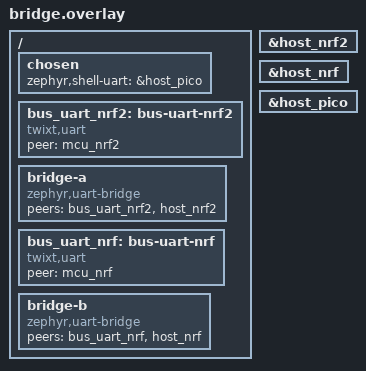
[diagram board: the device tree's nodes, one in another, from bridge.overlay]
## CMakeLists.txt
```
# Copyright (c) 2026 Christoph Jans <jans.christoph@gmail.com>
# SPDX-License-Identifier: Apache-2.0

cmake_minimum_required(VERSION 3.20.0)

# One image per MCU: nrf2 and nrf are boards with a shell, the bridge passes their shells on
# to the host. MCU picks which MCU of twixt_mcus.dtsi this image is.
# Under sysbuild (the Raspberry Pi Pico), -DMCU is in the sysbuild cache, not in this image's
if(SYSBUILD_CACHE)
  file(STRINGS ${SYSBUILD_CACHE} sysbuild_mcu REGEX "^MCU:")
  if(sysbuild_mcu)
    string(REGEX REPLACE "^MCU:[A-Z]*=" "" sysbuild_mcu "${sysbuild_mcu}")
    set(MCU ${sysbuild_mcu} CACHE STRING "" FORCE)
  endif()
  file(STRINGS ${SYSBUILD_CACHE} sysbuild_esp_peer REGEX "^stress_TWIXT_STRESS_ESP_PEER:")
  if(sysbuild_esp_peer)
    string(REGEX REPLACE "^stress_TWIXT_STRESS_ESP_PEER:[A-Z]*=" "" sysbuild_esp_peer "${sysbuild_esp_peer}")
    set(TWIXT_STRESS_ESP_PEER ${sysbuild_esp_peer} CACHE BOOL "" FORCE)
  endif()
endif()
set(MCU nrf2 CACHE STRING "MCU to build: nrf2, nrf, pico or esp")
if(MCU STREQUAL "pico")
  set(role bridge)
else()
  set(role board)
endif()
list(APPEND EXTRA_DTC_OVERLAY_FILE ${CMAKE_CURRENT_SOURCE_DIR}/${role}.overlay)
option(TWIXT_STRESS_ESP_PEER "Expose the ESP32 bus shell on the Pico bridge" OFF)
if(MCU STREQUAL "esp" OR TWIXT_STRESS_ESP_PEER)
  list(APPEND DTS_EXTRA_CPPFLAGS -DTWIXT_STRESS_WITH_ESP)
endif()
if(MCU STREQUAL "pico" AND TWIXT_STRESS_ESP_PEER)
  list(APPEND EXTRA_DTC_OVERLAY_FILE ${CMAKE_CURRENT_SOURCE_DIR}/esp-bridge.overlay)
endif()
list(APPEND DTS_EXTRA_CPPFLAGS -DTWIXT_SELF_LABEL=mcu_${MCU})

find_package(Zephyr REQUIRED HINTS $ENV{ZEPHYR_BASE})
project(twixt_stress)

target_sources(app PRIVATE src/${role}.c)
```

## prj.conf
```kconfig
# Copyright (c) 2026 Christoph Jans <jans.christoph@gmail.com>
# SPDX-License-Identifier: Apache-2.0

CONFIG_I2C=y
CONFIG_SERIAL=y
CONFIG_LOG=y
CONFIG_LOG_BACKEND_SHOW_COLOR=n

# Every MCU has a shell: the boards on a UART over the bus to the bridge, the bridge on its
# own port to the host. The log stays off the shell.
CONFIG_SHELL=y
CONFIG_SHELL_LOG_BACKEND=n
CONFIG_SHELL_VT100_COLORS=n
CONFIG_SHELL_STACK_SIZE=4096

# i2c scan i2c-mm
CONFIG_I2C_SHELL=y

# The echo load the test starts on every MCU: twixt stress
CONFIG_TWIXT_STRESS=y
```

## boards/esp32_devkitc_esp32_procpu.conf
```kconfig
# SPDX-License-Identifier: Apache-2.0
CONFIG_SMP=n
CONFIG_PM=n
CONFIG_I2C_TARGET_BUFFER_MODE=n
CONFIG_TWIXT_LINK_NACK_RETRY_MS=20
CONFIG_MAIN_STACK_SIZE=4096
CONFIG_ISR_STACK_SIZE=4096
CONFIG_LOG_BACKEND_UART=n
```

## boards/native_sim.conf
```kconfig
# Copyright (c) 2026 Christoph Jans <jans.christoph@gmail.com>
# SPDX-License-Identifier: Apache-2.0

# Three MCUs that all send all the time, on a host that is also busy: an MCU may lose arbitration
# for longer than the default before its turn comes. An error fails the test.
CONFIG_TWIXT_LINK_RETRY_MS=2000
```

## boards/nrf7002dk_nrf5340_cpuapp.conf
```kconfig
# Copyright (c) 2026 Christoph Jans <jans.christoph@gmail.com>
# SPDX-License-Identifier: Apache-2.0

# The TWIS driver hands over whole messages
CONFIG_I2C_TARGET_BUFFER_MODE=y
CONFIG_I2C_NRFX_TWIS_BUF_SIZE=64

# A peer NACKs during its own transfers: a request and a response of 64 bytes at 100 kHz
CONFIG_TWIXT_LINK_NACK_RETRY_MS=20
```

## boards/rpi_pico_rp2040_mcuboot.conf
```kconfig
# Copyright (c) 2026 Christoph Jans <jans.christoph@gmail.com>
# SPDX-License-Identifier: Apache-2.0

# The bridge's ports to the host: USB CDC-ACM, set up in src/bridge.c
CONFIG_USB_DEVICE_STACK_NEXT=y
CONFIG_USBD_CDC_ACM_CLASS=y
CONFIG_CDC_ACM_SERIAL_INITIALIZE_AT_BOOT=n
CONFIG_USBD_CDC_ACM_LOG_LEVEL_OFF=y


# A peer NACKs during its own transfers: a request and a response of 64 bytes at 100 kHz
CONFIG_TWIXT_LINK_NACK_RETRY_MS=20

# MCUmgr, to update the image over USB
CONFIG_MCUMGR=y
CONFIG_NET_BUF=y
CONFIG_ZCBOR=y
CONFIG_CRC=y
CONFIG_BASE64=y
CONFIG_FLASH=y
CONFIG_FLASH_MAP=y
CONFIG_STREAM_FLASH=y
CONFIG_IMG_MANAGER=y
CONFIG_IMG_ERASE_PROGRESSIVELY=y
CONFIG_MCUMGR_GRP_IMG=y
CONFIG_MCUMGR_GRP_OS=y
CONFIG_MCUMGR_GRP_OS_MCUMGR_PARAMS=y
CONFIG_REBOOT=y
CONFIG_SYSTEM_WORKQUEUE_STACK_SIZE=2048
CONFIG_UART_MCUMGR=y
CONFIG_MCUMGR_TRANSPORT_UART=y
```

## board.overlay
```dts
/*
 * Copyright (c) 2026 Christoph Jans <jans.christoph@gmail.com>
 *
 * SPDX-License-Identifier: Apache-2.0
 */

/* A board: its shell on a UART over the bus to the bridge */

/ {
	chosen {
		zephyr,shell-uart = &bus_uart;
	};

	bus_uart: bus-uart {
		compatible = "twixt,uart";
		peer = <&mcu_pico>;
	};
};
```

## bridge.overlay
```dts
/*
 * Copyright (c) 2026 Christoph Jans <jans.christoph@gmail.com>
 *
 * SPDX-License-Identifier: Apache-2.0
 */

/* The bridge: per board a UART over the bus, bridged to a port to the host, host_<board>; its
 * own shell on host_pico. The board's overlay (boards/) has the ports, disabled: PTYs on native_sim,
 * USB CDC-ACM on the Raspberry Pi Pico.
 */

/ {
	chosen {
		zephyr,shell-uart = &host_pico;
	};

	bus_uart_nrf2: bus-uart-nrf2 {
		compatible = "twixt,uart";
		peer = <&mcu_nrf2>;
	};

	bridge-a {
		compatible = "zephyr,uart-bridge";
		peers = <&bus_uart_nrf2 &host_nrf2>;
	};

	bus_uart_nrf: bus-uart-nrf {
		compatible = "twixt,uart";
		peer = <&mcu_nrf>;
	};

	bridge-b {
		compatible = "zephyr,uart-bridge";
		peers = <&bus_uart_nrf &host_nrf>;
	};
};

&host_nrf2 {
	status = "okay";
};

&host_nrf {
	status = "okay";
};

&host_pico {
	status = "okay";
};
```

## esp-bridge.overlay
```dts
/* SPDX-License-Identifier: Apache-2.0 */
/* Optional ESP32 peer: append a USB port without renumbering existing ports. */

/ {
	bus_uart_esp: bus-uart-esp {
		compatible = "twixt,uart";
		peer = <&mcu_esp>;
	};

	bridge-esp {
		compatible = "zephyr,uart-bridge";
		peers = <&bus_uart_esp &host_esp>;
	};
};

&zephyr_udc0 {
	host_esp: host-esp {
		compatible = "zephyr,cdc-acm-uart";
		label = "twixt board esp";
	};
};
```

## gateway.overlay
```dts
/*
 * Copyright (c) 2026 Christoph Jans <jans.christoph@gmail.com>
 *
 * SPDX-License-Identifier: Apache-2.0
 */

/* The gateway: per board a UART over the bus, bridged to a port to the host, host_<board>; its
 * own shell on host_gw. The board's overlay (boards/) has the ports, disabled: PTYs on native_sim,
 * USB CDC-ACM on the Raspberry Pi Pico.
 */

/ {
	chosen {
		zephyr,shell-uart = &host_gw;
	};

	bus_uart_a: bus-uart-a {
		compatible = "twixt,uart";
		peer = <&mcu_a>;
	};

	bridge-a {
		compatible = "zephyr,uart-bridge";
		peers = <&bus_uart_a &host_a>;
	};

	bus_uart_b: bus-uart-b {
		compatible = "twixt,uart";
		peer = <&mcu_b>;
	};

	bridge-b {
		compatible = "zephyr,uart-bridge";
		peers = <&bus_uart_b &host_b>;
	};
};

&host_a {
	status = "okay";
};

&host_b {
	status = "okay";
};

&host_gw {
	status = "okay";
};
```

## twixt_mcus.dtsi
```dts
/*
 * Copyright (c) 2026 Christoph Jans <jans.christoph@gmail.com>
 *
 * SPDX-License-Identifier: Apache-2.0
 */

mcu_nrf2: nrf2@10 {
	compatible = "twixt,mcu";
	reg = <0x10>;
};

mcu_nrf: nrf@11 {
	compatible = "twixt,mcu";
	reg = <0x11>;
};

mcu_pico: pico@70 {
	compatible = "twixt,mcu";
	reg = <0x70>;
};

#ifdef TWIXT_STRESS_WITH_ESP
mcu_esp: esp@12 {
	compatible = "twixt,mcu";
	reg = <0x12>;
};
#endif
```

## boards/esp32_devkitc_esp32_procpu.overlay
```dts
/* SPDX-License-Identifier: Apache-2.0 */
#include <zephyr/dt-bindings/i2c/i2c.h>

/ {
	chosen {
		twixt,self = &mcu_esp;
	};

	i2c-mm {
		compatible = "twixt,i2c-mm-gpio";
		target = <&i2c0>;
		scl-gpios = <&gpio0 22 0>;
		sda-gpios = <&gpio0 21 0>;
		clock-frequency = <I2C_BITRATE_STANDARD>;
		#address-cells = <1>;
		#size-cells = <0>;
#include "../twixt_mcus.dtsi"
	};
};

&i2c0 {
	compatible = "twixt,esp32-i2c-target";
	status = "okay";
	port = <0>;
	scl-gpios = <&gpio0 22 0>;
	sda-gpios = <&gpio0 21 0>;
};

/* Same priority as the target I2C ISR, on the sole enabled core. */
&gpio0 {
	interrupts = <GPIO_INTR_SOURCE 3 0>;
};
```

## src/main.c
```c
/*
 * Copyright (c) 2026 Christoph Jans <jans.christoph@gmail.com>
 *
 * SPDX-License-Identifier: Apache-2.0
 *
 * Stress test of twixt: one MCU of three on a bus of equal peers.
 *
 * This image is one MCU. Its settings (Zephyr settings subsystem, subtree
 * "mcu") are read-only (r) or read/write (rw), and all MCUs get and set them by
 * name over the bus (twixt/settings.h):
 *
 *   mcu/name       r   the devicetree node of the MCU
 *   mcu/version    r   APP_VERSION
 *   mcu/counter    r   the rounds of this MCU so far
 *   mcu/dump0..2   rw  any bytes, up to TWIXT_SETTINGS_VALUE_MAX; kept in flash
 *
 * First every MCU pings the others: same protocol version, same limits. Then
 * every round, all MCUs at the very same moment send a random request to a
 * random MCU, maybe themselves, so the requests collide on the bus and the
 * lowest frame wins the arbitration; a little later they send another one. They
 * check the answer:
 *  - name and version are what the devicetree and the build say,
 *  - a counter never goes back, and cannot be set,
 *  - a dump is whole: whoever set it put a CRC into its last byte,
 *  - a setting that does not exist is not there.
 *
 * The MCUs on the bus and their I2C addresses are devicetree
 * (boards/native_sim.overlay, compatible "twixt,mcu"); the one this
 * image runs on is /chosen twixt,self, picked by -DMCU=<a|b|c>.
 */

#include <stdio.h>
#include <string.h>
#include <zephyr/device.h>
#include <zephyr/kernel.h>
#include <zephyr/spinlock.h>
#include <zephyr/logging/log.h>
#include <zephyr/random/random.h>
#include <zephyr/settings/settings.h>
#include <zephyr/sys/crc.h>

#include <drivers/i2c/i2c_mm_native.h>
#include <twixt/twixt.h>
#include <twixt/ping.h>
#include <twixt/settings.h>

LOG_MODULE_REGISTER(main, LOG_LEVEL_INF);

#define I2C_DEV DEVICE_DT_GET(DT_BUS(TWIXT_SELF))

#define APP_VERSION "1.0.0"
#define DUMPS       3
#define ROUNDS      20
#define PERIOD_MS   100
#define PROBE_ADDR  0x55 /* nobody there */

#define MCU(node)  DT_REG_ADDR(node),
#define NAME(node) DT_NODE_FULL_NAME(node),

static const uint8_t mcus[] = {DT_FOREACH_STATUS_OKAY(twixt_mcu, MCU)};
static const char *const names[] = {DT_FOREACH_STATUS_OKAY(twixt_mcu, NAME)};

#define NUM_MCUS ARRAY_SIZE(mcus)

BUILD_ASSERT(NUM_MCUS > 1, "no other MCU on the bus");

static uint32_t bad; /* checks that failed */

/*
 * The handlers run in the I2C target interrupt for the other MCUs, and in
 * threads for this one (settings_load(), settings_save(), any local use of the
 * settings API): `lock` keeps every value whole.
 */
static struct k_spinlock lock;
static uint32_t counter;
static struct {
	uint8_t len; /* 0: not set */
	uint8_t data[TWIXT_SETTINGS_VALUE_MAX];
} dumps[DUMPS];

/* "dump<i>" to i, or -1 */
static int dump_index(const char *key)
{
	if (strncmp(key, "dump", 4) == 0 && key[4] >= '0' && key[4] < '0' + DUMPS &&
	    key[5] == '\0') {
		return key[4] - '0';
	}
	return -1;
}

static int mcu_get(const char *key, char *val, int val_len_max)
{
	int i = dump_index(key);
	const void *src = NULL;
	int len = -ENOENT;

	if (settings_name_steq(key, "name", NULL)) {
		src = twixt_self_name();
		len = strlen(twixt_self_name());
	} else if (settings_name_steq(key, "version", NULL)) {
		src = APP_VERSION;
		len = strlen(APP_VERSION);
	} else if (settings_name_steq(key, "counter", NULL)) {
		src = &counter;
		len = sizeof(counter);
	}

	K_SPINLOCK(&lock) {
		if (i >= 0) {
			src = dumps[i].data;
			len = dumps[i].len > 0 ? dumps[i].len : -ENOENT;
		}
		if (len > val_len_max) {
			len = -ENOMEM;
		} else if (len > 0) {
			memcpy(val, src, len);
		}
	}
	return len;
}

/* Called by settings_load() with the stored dumps, and for a SET */
static int mcu_set(const char *key, size_t len, settings_read_cb read_cb, void *cb_arg)
{
	uint8_t data[TWIXT_SETTINGS_VALUE_MAX];
	int i = dump_index(key);
	ssize_t ret;

	if (settings_name_steq(key, "name", NULL) || settings_name_steq(key, "version", NULL) ||
	    settings_name_steq(key, "counter", NULL)) {
		return -EACCES;
	}
	if (i < 0) {
		return -ENOENT;
	}
	if (len == 0 || len > sizeof(dumps[i].data)) {
		return -EINVAL;
	}
	ret = read_cb(cb_arg, data, len); /* not under the lock: may read flash */
	if (ret < 0) {
		return ret;
	}
	K_SPINLOCK(&lock) {
		memcpy(dumps[i].data, data, len);
		dumps[i].len = len;
	}
	return 0;
}

/* Called by settings_save(): the rw settings go to flash */
static int mcu_export(int (*export_func)(const char *name, const void *val, size_t val_len))
{
	for (int i = 0; i < DUMPS; i++) {
		uint8_t data[TWIXT_SETTINGS_VALUE_MAX];
		char name[sizeof("mcu/dump0")];
		uint8_t len;

		K_SPINLOCK(&lock) { /* not export_func() under the lock: it writes flash */
			len = dumps[i].len;
			memcpy(data, dumps[i].data, len);
		}

		if (len > 0) {
			snprintf(name, sizeof(name), "mcu/dump%c", '0' + i);
			export_func(name, data, len);
		}
	}
	return 0;
}

SETTINGS_STATIC_HANDLER_DEFINE(mcu, "mcu", mcu_get, mcu_set, NULL, mcu_export);

/*
 * Random number in 0..n-1. Not `% n`: the host random() behind the native_sim
 * entropy driver has a weak lowest bit, and with consecutive seeds all MCUs
 * would draw the same sequence. Bits 8..23 are fine.
 */
static uint32_t rand_below(uint32_t n)
{
	return (((sys_rand32_get() >> 8) & 0xffff) * n) >> 16;
}

static uint8_t dump_crc(const uint8_t *data, int len)
{
	return crc8_ccitt(0x00, data, len - 1);
}

static void check(uint8_t round, uint8_t addr, const char *what, bool ok, int ret)
{
	if (ok) {
		LOG_INF("round %u: 0x%02x %s: %d", round, addr, what, ret);
	} else {
		LOG_ERR("round %u: 0x%02x %s: unexpected %d", round, addr, what, ret);
		bad++;
	}
}

static void random_request(uint8_t round)
{
	static uint32_t last_counter[NUM_MCUS];
	int t = rand_below(NUM_MCUS);
	uint8_t addr = mcus[t];
	uint8_t buf[TWIXT_SETTINGS_VALUE_MAX + 1] = {0}; /* room for a NUL */
	char dump[sizeof("mcu/dump0")];
	char what[sizeof("get mcu/dump0")];
	uint32_t value = 0;
	int len;
	int ret;

	snprintf(dump, sizeof(dump), "mcu/dump%c", '0' + (int)rand_below(DUMPS));

	switch (rand_below(7)) {
	case 0:
		ret = twixt_settings_get(addr, "mcu/name", buf, TWIXT_SETTINGS_VALUE_MAX);
		check(round, addr, "get mcu/name", ret > 0 && strcmp(buf, names[t]) == 0, ret);
		break;
	case 1:
		ret = twixt_settings_get(addr, "mcu/version", buf, TWIXT_SETTINGS_VALUE_MAX);
		check(round, addr, "get mcu/version", ret > 0 && strcmp(buf, APP_VERSION) == 0,
		      ret);
		break;
	case 2:
		ret = twixt_settings_get(addr, "mcu/counter", &value, sizeof(value));
		check(round, addr, "get mcu/counter",
		      ret == sizeof(value) && value >= last_counter[t], ret);
		last_counter[t] = MAX(last_counter[t], value);
		break;
	case 3:
		ret = twixt_settings_set(addr, "mcu/counter", &value, sizeof(value));
		check(round, addr, "set mcu/counter (read-only)", ret == -EACCES, ret);
		break;
	case 4:
		len = 2 + rand_below(TWIXT_SETTINGS_VALUE_MAX - 1);
		sys_rand_get(buf, len - 1);
		buf[len - 1] = dump_crc(buf, len);
		ret = twixt_settings_set(addr, dump, buf, len);
		snprintf(what, sizeof(what), "set %s", dump);
		check(round, addr, what, ret == 0, ret);
		break;
	case 5:
		ret = twixt_settings_get(addr, dump, buf, TWIXT_SETTINGS_VALUE_MAX);
		snprintf(what, sizeof(what), "get %s", dump); /* not set, or whole */
		check(round, addr, what,
		      ret == -ENOENT || (ret >= 2 && buf[ret - 1] == dump_crc(buf, ret)), ret);
		break;
	default:
		ret = twixt_settings_get(addr, "mcu/nothing", buf, TWIXT_SETTINGS_VALUE_MAX);
		check(round, addr, "get mcu/nothing", ret == -ENOENT, ret);
		break;
	}
}

int main(void)
{
	struct i2c_mm_native_stats s;
	struct i2c_mm_stats bus;
	uint8_t byte;
	int ret;

	ret = settings_subsys_init();
	if (ret == 0) {
		ret = settings_load();
	}
	if (ret) {
		LOG_ERR("%s: cannot load the settings: %d", twixt_self_name(), ret);
		return ret;
	}
	LOG_INF("%s at 0x%02x, version %s; dumps from flash: %u, %u, %u bytes", twixt_self_name(),
		twixt_self_addr(), APP_VERSION, dumps[0].len, dumps[1].len, dumps[2].len);

	/* Test bench: the other MCUs are processes that start at their own pace */
	ret = i2c_mm_native_wait_targets(I2C_DEV, NUM_MCUS);
	if (ret) {
		LOG_ERR("%s: the other MCUs did not show up", twixt_self_name());
		return ret;
	}

	for (int i = 0; i < NUM_MCUS; i++) {
		struct twixt_ping_info info;

		ret = twixt_ping(mcus[i], &info);
		check(0, mcus[i], "ping", ret == 0, ret);
	}

	ret = twixt_settings_get(PROBE_ADDR, "mcu/name", &byte, 1);
	check(0, PROBE_ADDR, "get mcu/name (nobody there)", ret == -EIO, ret);

	for (uint8_t round = 0; round < ROUNDS; round++) {
		i2c_mm_native_wait_round(I2C_DEV, round, PERIOD_MS);
		K_SPINLOCK(&lock) {
			counter++;
		}
		random_request(round);
		k_msleep(rand_below(PERIOD_MS / 2));
		random_request(round);
	}

	/* After that nobody sends any more: the counts are final */
	ret = i2c_mm_native_wait_done(I2C_DEV, NUM_MCUS);
	if (ret) {
		LOG_ERR("%s: the other MCUs did not finish", twixt_self_name());
		return ret;
	}

	i2c_mm_native_get_stats(I2C_DEV, &s);
	twixt_get_stats(&bus);
	LOG_INF("sent %u requests, served %u requests; %u bad; %u retries; lost arbitration %u, "
		"bus timeouts %u, nacks %u, irqs %u",
		bus.sent, bus.served, bad, bus.retries, s.arb_lost, s.bus_timeouts, s.nacks,
		s.irqs);

	/* How much an MCU serves is up to the others: pytest/test_stress.py checks that every
	 * request that was sent was served
	 */
	if (bad == 0) {
		LOG_INF("all settings verified");
	} else {
		LOG_ERR("settings check failed");
	}
	return 0;
}
```

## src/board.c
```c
/*
 * Copyright (c) 2026 Christoph Jans <jans.christoph@gmail.com>
 *
 * SPDX-License-Identifier: Apache-2.0
 *
 * A board: its shell is on a UART over the bus to the bridge (board.overlay), where the test
 * starts and reads "twixt stress". The prompt is its name: nrf2@10:~$
 */

#include <stdio.h>
#include <zephyr/kernel.h>
#include <zephyr/logging/log.h>
#include <zephyr/shell/shell_uart.h>

#include <twixt/twixt.h>

LOG_MODULE_REGISTER(board, LOG_LEVEL_INF);

int main(void)
{
	static char prompt[32];

	snprintf(prompt, sizeof(prompt), "%s:~$ ", twixt_self_name());
	shell_prompt_change(shell_backend_uart_get_ptr(), prompt);

	LOG_INF("%s at 0x%02x, shell on the bus", twixt_self_name(), twixt_self_addr());
	return 0;
}
```

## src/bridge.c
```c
/*
 * Copyright (c) 2026 Christoph Jans <jans.christoph@gmail.com>
 *
 * SPDX-License-Identifier: Apache-2.0
 *
 * The bridge: bridges the boards' shells to the host, and has its own shell, the prompt its
 * name: pico@70:~$ (bridge.overlay). With USB CDC-ACM ports (Raspberry Pi Pico), it brings up
 * the USB device with all of them.
 */

#include <stdio.h>
#include <zephyr/kernel.h>
#include <zephyr/logging/log.h>
#include <zephyr/shell/shell_uart.h>

#include <twixt/twixt.h>

LOG_MODULE_REGISTER(bridge, LOG_LEVEL_INF);

#if DT_HAS_COMPAT_STATUS_OKAY(zephyr_cdc_acm_uart)

#include <zephyr/usb/usbd.h>

/* Zephyr's VID and a PID for testing; a product needs its own */
USBD_DEVICE_DEFINE(bridge_usbd, DEVICE_DT_GET(DT_NODELABEL(zephyr_udc0)), 0x2fe3, 0x0004);
USBD_DESC_LANG_DEFINE(bridge_lang);
USBD_DESC_MANUFACTURER_DEFINE(bridge_mfr, "twixt");
USBD_DESC_PRODUCT_DEFINE(bridge_product, "twixt pico");
USBD_DESC_CONFIG_DEFINE(bridge_cfg_desc, "FS Configuration");
USBD_CONFIGURATION_DEFINE(bridge_config, 0, 125, &bridge_cfg_desc);

static int usb_init(void)
{
	struct usbd_desc_node *const descs[] = {&bridge_lang, &bridge_mfr, &bridge_product};
	int err;

	for (size_t i = 0; i < ARRAY_SIZE(descs); i++) {
		err = usbd_add_descriptor(&bridge_usbd, descs[i]);
		if (err) {
			return err;
		}
	}
	err = usbd_add_configuration(&bridge_usbd, USBD_SPEED_FS, &bridge_config);
	if (err) {
		return err;
	}
	err = usbd_register_all_classes(&bridge_usbd, USBD_SPEED_FS, 1, NULL);
	if (err) {
		return err;
	}
	/* CDC-ACM has more than one interface per port: interface association */
	usbd_device_set_code_triple(&bridge_usbd, USBD_SPEED_FS, USB_BCC_MISCELLANEOUS, 0x02, 0x01);

	err = usbd_init(&bridge_usbd);
	if (err) {
		return err;
	}
	return usbd_enable(&bridge_usbd);
}

#endif

int main(void)
{
	static char prompt[32];

#if DT_HAS_COMPAT_STATUS_OKAY(zephyr_cdc_acm_uart)
	int err = usb_init();

	if (err) {
		LOG_ERR("USB: %d", err);
	}
#endif
	snprintf(prompt, sizeof(prompt), "%s:~$ ", twixt_self_name());
	shell_prompt_change(shell_backend_uart_get_ptr(), prompt);

	LOG_INF("%s at 0x%02x: bridge", twixt_self_name(), twixt_self_addr());
	return 0;
}
```

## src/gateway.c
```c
/*
 * Copyright (c) 2026 Christoph Jans <jans.christoph@gmail.com>
 *
 * SPDX-License-Identifier: Apache-2.0
 *
 * The gateway: bridges the boards' shells to the host, and has its own shell, the prompt its
 * name: gw@70:~$ (gateway.overlay). With USB CDC-ACM ports (Raspberry Pi Pico), it brings up
 * the USB device with all of them.
 */

#include <stdio.h>
#include <zephyr/kernel.h>
#include <zephyr/logging/log.h>
#include <zephyr/shell/shell_uart.h>

#include <twixt/twixt.h>

LOG_MODULE_REGISTER(gateway, LOG_LEVEL_INF);

#if DT_HAS_COMPAT_STATUS_OKAY(zephyr_cdc_acm_uart)

#include <zephyr/usb/usbd.h>

/* Zephyr's VID and a PID for testing; a product needs its own */
USBD_DEVICE_DEFINE(gw_usbd, DEVICE_DT_GET(DT_NODELABEL(zephyr_udc0)), 0x2fe3, 0x0004);
USBD_DESC_LANG_DEFINE(gw_lang);
USBD_DESC_MANUFACTURER_DEFINE(gw_mfr, "twixt");
USBD_DESC_PRODUCT_DEFINE(gw_product, "twixt pico");
USBD_DESC_CONFIG_DEFINE(gw_cfg_desc, "FS Configuration");
USBD_CONFIGURATION_DEFINE(gw_config, 0, 125, &gw_cfg_desc);

static int usb_init(void)
{
	struct usbd_desc_node *const descs[] = {&gw_lang, &gw_mfr, &gw_product};
	int err;

	for (size_t i = 0; i < ARRAY_SIZE(descs); i++) {
		err = usbd_add_descriptor(&gw_usbd, descs[i]);
		if (err) {
			return err;
		}
	}
	err = usbd_add_configuration(&gw_usbd, USBD_SPEED_FS, &gw_config);
	if (err) {
		return err;
	}
	err = usbd_register_all_classes(&gw_usbd, USBD_SPEED_FS, 1, NULL);
	if (err) {
		return err;
	}
	/* CDC-ACM has more than one interface per port: interface association */
	usbd_device_set_code_triple(&gw_usbd, USBD_SPEED_FS, USB_BCC_MISCELLANEOUS, 0x02, 0x01);

	err = usbd_init(&gw_usbd);
	if (err) {
		return err;
	}
	return usbd_enable(&gw_usbd);
}

#endif

int main(void)
{
	static char prompt[32];

#if DT_HAS_COMPAT_STATUS_OKAY(zephyr_cdc_acm_uart)
	int err = usb_init();

	if (err) {
		LOG_ERR("USB: %d", err);
	}
#endif
	snprintf(prompt, sizeof(prompt), "%s:~$ ", twixt_self_name());
	shell_prompt_change(shell_backend_uart_get_ptr(), prompt);

	LOG_INF("%s at 0x%02x: gateway", twixt_self_name(), twixt_self_addr());
	return 0;
}
```
